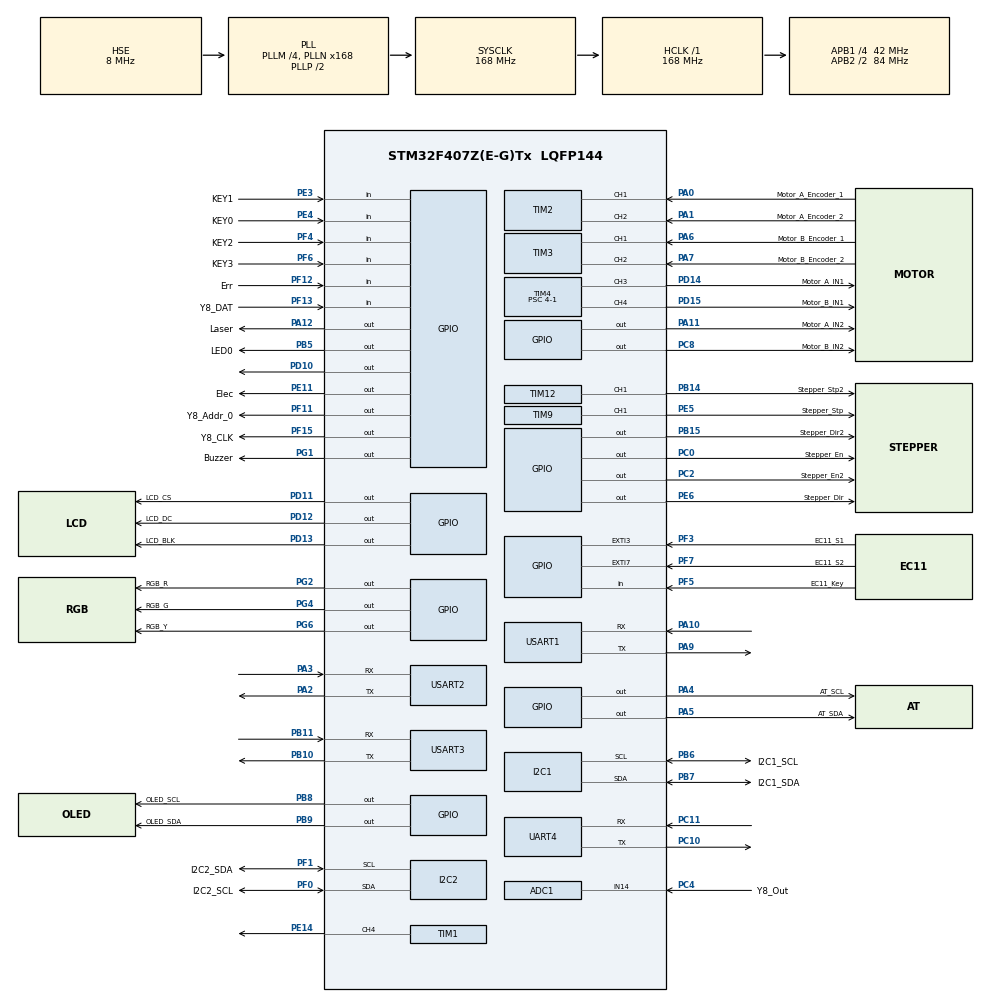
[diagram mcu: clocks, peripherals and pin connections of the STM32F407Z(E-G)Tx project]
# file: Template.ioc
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ADC1.Channel-1\#ChannelRegularConversion=ADC_CHANNEL_14
ADC1.NbrOfConversionFlag=1
ADC1.Rank-1\#ChannelRegularConversion=1
ADC1.SamplingTime-1\#ChannelRegularConversion=ADC_SAMPLETIME_3CYCLES
ADC1.master=1
Dma.Request0=USART1_RX
Dma.Request1=USART1_TX
Dma.Request2=USART2_RX
Dma.Request3=USART2_TX
Dma.Request4=UART4_RX
Dma.Request5=UART4_TX
Dma.Request6=USART3_RX
Dma.UART4_RX.4.Direction=DMA_PERIPH_TO_MEMORY
Dma.UART4_RX.4.FIFOMode=DMA_FIFOMODE_DISABLE
Dma.UART4_RX.4.Instance=DMA1_Stream2
Dma.UART4_RX.4.MemDataAlignment=DMA_MDATAALIGN_BYTE
Dma.UART4_RX.4.MemInc=DMA_MINC_ENABLE
Dma.UART4_RX.4.Mode=DMA_NORMAL
Dma.UART4_RX.4.PeriphDataAlignment=DMA_PDATAALIGN_BYTE
Dma.UART4_RX.4.PeriphInc=DMA_PINC_DISABLE
Dma.UART4_RX.4.Priority=DMA_PRIORITY_LOW
Dma.UART4_TX.5.Direction=DMA_MEMORY_TO_PERIPH
Dma.UART4_TX.5.FIFOMode=DMA_FIFOMODE_DISABLE
Dma.UART4_TX.5.Instance=DMA1_Stream4
Dma.UART4_TX.5.MemDataAlignment=DMA_MDATAALIGN_BYTE
Dma.UART4_TX.5.MemInc=DMA_MINC_ENABLE
Dma.UART4_TX.5.Mode=DMA_NORMAL
Dma.UART4_TX.5.PeriphDataAlignment=DMA_PDATAALIGN_BYTE
Dma.UART4_TX.5.PeriphInc=DMA_PINC_DISABLE
Dma.UART4_TX.5.Priority=DMA_PRIORITY_LOW
Dma.USART1_RX.0.Direction=DMA_PERIPH_TO_MEMORY
Dma.USART1_RX.0.FIFOMode=DMA_FIFOMODE_DISABLE
Dma.USART1_RX.0.Instance=DMA2_Stream2
Dma.USART1_RX.0.MemDataAlignment=DMA_MDATAALIGN_BYTE
Dma.USART1_RX.0.MemInc=DMA_MINC_ENABLE
Dma.USART1_RX.0.Mode=DMA_NORMAL
Dma.USART1_RX.0.PeriphDataAlignment=DMA_PDATAALIGN_BYTE
Dma.USART1_RX.0.PeriphInc=DMA_PINC_DISABLE
Dma.USART1_RX.0.Priority=DMA_PRIORITY_LOW
Dma.USART1_TX.1.Direction=DMA_MEMORY_TO_PERIPH
Dma.USART1_TX.1.FIFOMode=DMA_FIFOMODE_DISABLE
Dma.USART1_TX.1.Instance=DMA2_Stream7
Dma.USART1_TX.1.MemDataAlignment=DMA_MDATAALIGN_BYTE
Dma.USART1_TX.1.MemInc=DMA_MINC_ENABLE
Dma.USART1_TX.1.Mode=DMA_NORMAL
Dma.USART1_TX.1.PeriphDataAlignment=DMA_PDATAALIGN_BYTE
Dma.USART1_TX.1.PeriphInc=DMA_PINC_DISABLE
Dma.USART1_TX.1.Priority=DMA_PRIORITY_LOW
Dma.USART2_RX.2.Direction=DMA_PERIPH_TO_MEMORY
Dma.USART2_RX.2.FIFOMode=DMA_FIFOMODE_DISABLE
Dma.USART2_RX.2.Instance=DMA1_Stream5
Dma.USART2_RX.2.MemDataAlignment=DMA_MDATAALIGN_BYTE
Dma.USART2_RX.2.MemInc=DMA_MINC_ENABLE
Dma.USART2_RX.2.Mode=DMA_NORMAL
Dma.USART2_RX.2.PeriphDataAlignment=DMA_PDATAALIGN_BYTE
Dma.USART2_RX.2.PeriphInc=DMA_PINC_DISABLE
Dma.USART2_RX.2.Priority=DMA_PRIORITY_LOW
Dma.USART2_TX.3.Direction=DMA_MEMORY_TO_PERIPH
Dma.USART2_TX.3.FIFOMode=DMA_FIFOMODE_DISABLE
Dma.USART2_TX.3.Instance=DMA1_Stream6
Dma.USART2_TX.3.MemDataAlignment=DMA_MDATAALIGN_BYTE
Dma.USART2_TX.3.MemInc=DMA_MINC_ENABLE
Dma.USART2_TX.3.Mode=DMA_NORMAL
Dma.USART2_TX.3.PeriphDataAlignment=DMA_PDATAALIGN_BYTE
Dma.USART2_TX.3.PeriphInc=DMA_PINC_DISABLE
Dma.USART2_TX.3.Priority=DMA_PRIORITY_LOW
Dma.USART3_RX.6.Direction=DMA_PERIPH_TO_MEMORY
Dma.USART3_RX.6.FIFOMode=DMA_FIFOMODE_DISABLE
Dma.USART3_RX.6.Instance=DMA1_Stream1
Dma.USART3_RX.6.MemDataAlignment=DMA_MDATAALIGN_BYTE
Dma.USART3_RX.6.MemInc=DMA_MINC_ENABLE
Dma.USART3_RX.6.Mode=DMA_NORMAL
Dma.USART3_RX.6.PeriphDataAlignment=DMA_PDATAALIGN_BYTE
Dma.USART3_RX.6.PeriphInc=DMA_PINC_DISABLE
Dma.USART3_RX.6.Priority=DMA_PRIORITY_LOW
Mcu.Family=STM32F4
Mcu.Name=STM32F407Z(E-G)Tx
Mcu.Package=LQFP144
NVIC.DMA1_Stream1_IRQn=true\:0\:0\:false\:false\:true\:false\:true\:true
NVIC.DMA1_Stream2_IRQn=true\:0\:0\:false\:false\:true\:false\:true\:true
NVIC.DMA1_Stream4_IRQn=true\:0\:0\:false\:false\:true\:false\:true\:true
NVIC.DMA1_Stream5_IRQn=true\:0\:0\:false\:false\:true\:false\:true\:true
NVIC.DMA1_Stream6_IRQn=true\:0\:0\:false\:false\:true\:false\:true\:true
NVIC.DMA2_Stream2_IRQn=true\:0\:0\:false\:false\:true\:false\:true\:true
NVIC.DMA2_Stream7_IRQn=true\:0\:0\:false\:false\:true\:false\:true\:true
NVIC.EXTI3_IRQn=true\:0\:0\:false\:false\:true\:true\:true\:true
NVIC.EXTI9_5_IRQn=true\:0\:0\:false\:false\:true\:true\:true\:true
NVIC.PriorityGroup=NVIC_PRIORITYGROUP_2
NVIC.TIM1_UP_TIM10_IRQn=true\:0\:0\:false\:false\:true\:true\:true\:true
NVIC.TIM6_DAC_IRQn=true\:0\:0\:false\:false\:true\:true\:true\:true
NVIC.TIM7_IRQn=true\:0\:0\:false\:false\:true\:true\:true\:true
NVIC.UART4_IRQn=true\:0\:0\:false\:false\:true\:true\:true\:true
NVIC.USART1_IRQn=true\:0\:0\:false\:false\:true\:true\:true\:true
NVIC.USART2_IRQn=true\:0\:0\:false\:false\:true\:true\:true\:true
NVIC.USART3_IRQn=true\:0\:0\:false\:false\:true\:true\:true\:true
PA0-WKUP.GPIO_Label=Motor_A_Encoder_1
PA0-WKUP.Signal=S_TIM2_CH1_ETR
PA1.GPIO_Label=Motor_A_Encoder_2
PA1.Signal=S_TIM2_CH2
PA10.Mode=Asynchronous
PA10.Signal=USART1_RX
PA11.GPIO_Label=Motor_A_IN2
PA11.Signal=GPIO_Output
PA12.GPIO_Label=Laser
PA12.Signal=GPIO_Output
PA13.Mode=Serial_Wire
PA13.Signal=SYS_JTMS-SWDIO
PA14.Mode=Serial_Wire
PA14.Signal=SYS_JTCK-SWCLK
PA2.Mode=Asynchronous
PA2.Signal=USART2_TX
PA3.Mode=Asynchronous
PA3.Signal=USART2_RX
PA4.GPIO_Label=AT_SCL
PA4.Signal=GPIO_Output
PA5.GPIO_Label=AT_SDA
PA5.Signal=GPIO_Output
PA6.GPIO_Label=Motor_B_Encoder_1
PA6.Signal=S_TIM3_CH1
PA7.GPIO_Label=Motor_B_Encoder_2
PA7.Signal=S_TIM3_CH2
PA8.Signal=I2C3_SCL
PA9.Mode=Asynchronous
PA9.Signal=USART1_TX
PB10.Mode=Asynchronous
PB10.Signal=USART3_TX
PB11.Mode=Asynchronous
PB11.Signal=USART3_RX
PB14.GPIO_Label=Stepper_Stp2
PB14.Signal=S_TIM12_CH1
PB15.GPIO_Label=Stepper_Dir2
PB15.Signal=GPIO_Output
PB3.Signal=SPI3_SCK
PB5.GPIO_Label=LED0
PB5.Signal=GPIO_Output
PB6.GPIO_Label=I2C1_SCL
PB6.Mode=I2C
PB6.Signal=I2C1_SCL
PB7.GPIO_Label=I2C1_SDA
PB7.Mode=I2C
PB7.Signal=I2C1_SDA
PB8.GPIO_Label=OLED_SCL
PB8.GPIO_Speed=GPIO_SPEED_FREQ_HIGH
PB8.Signal=GPIO_Output
PB9.GPIO_Label=OLED_SDA
PB9.GPIO_Speed=GPIO_SPEED_FREQ_HIGH
PB9.Signal=GPIO_Output
PC0.GPIO_Label=Stepper_En
PC0.PinState=GPIO_PIN_SET
PC0.Signal=GPIO_Output
PC10.Mode=Asynchronous
PC10.Signal=UART4_TX
PC11.Mode=Asynchronous
PC11.Signal=UART4_RX
PC14-OSC32_IN.Mode=LSE-External-Oscillator
PC14-OSC32_IN.Signal=RCC_OSC32_IN
PC15-OSC32_OUT.Mode=LSE-External-Oscillator
PC15-OSC32_OUT.Signal=RCC_OSC32_OUT
PC2.GPIO_Label=Stepper_En2
PC2.PinState=GPIO_PIN_SET
PC2.Signal=GPIO_Output
PC4.GPIO_Label=Y8_Out
PC4.Signal=ADCx_IN14
PC6.Signal=USART6_TX
PC7.Signal=USART6_RX
PC8.GPIO_Label=Motor_B_IN2
PC8.Signal=GPIO_Output
PC9.Signal=I2C3_SDA
PD10.Signal=GPIO_Output
PD11.GPIO_Label=LCD_CS
PD11.Signal=GPIO_Output
PD12.GPIO_Label=LCD_DC
PD12.Signal=GPIO_Output
PD13.GPIO_Label=LCD_BLK
PD13.Signal=GPIO_Output
PD14.GPIO_Label=Motor_A_IN1
PD14.Signal=S_TIM4_CH3
PD15.GPIO_Label=Motor_B_IN1
PD15.Signal=S_TIM4_CH4
PE11.GPIO_Label=Elec
PE11.Signal=GPIO_Output
PE14.Signal=S_TIM1_CH4
PE3.GPIO_Label=KEY1
PE3.GPIO_Mode=GPIO_MODE_INPUT
PE3.GPIO_PuPd=GPIO_PULLUP
PE3.Signal=GPIO_Input
PE4.GPIO_Label=KEY0
PE4.GPIO_Mode=GPIO_MODE_INPUT
PE4.GPIO_PuPd=GPIO_PULLUP
PE4.Signal=GPIO_Input
PE5.GPIO_Label=Stepper_Stp
PE5.Signal=S_TIM9_CH1
PE6.GPIO_Label=Stepper_Dir
PE6.PinState=GPIO_PIN_SET
PE6.Signal=GPIO_Output
PF0.GPIO_Label=I2C2_SCL
PF0.Mode=I2C
PF0.Signal=I2C2_SDA
PF1.GPIO_Label=I2C2_SDA
PF1.Mode=I2C
PF1.Signal=I2C2_SCL
PF11.GPIO_Label=Y8_Addr_0
PF11.Signal=GPIO_Output
PF12.GPIO_Label=Err
PF12.Signal=GPIO_Input
PF13.GPIO_Label=Y8_DAT
PF13.GPIO_PuPd=GPIO_PULLUP
PF13.Signal=GPIO_Input
PF15.GPIO_Label=Y8_CLK
PF15.GPIO_Speed=GPIO_SPEED_FREQ_MEDIUM
PF15.Signal=GPIO_Output
PF3.GPIO_Label=EC11_S1
PF3.GPIO_ModeDefaultEXTI=GPIO_MODE_IT_FALLING
PF3.GPIO_PuPd=GPIO_PULLUP
PF3.Signal=GPXTI3
PF4.GPIO_Label=KEY2
PF4.GPIO_PuPd=GPIO_PULLUP
PF4.Signal=GPIO_Input
PF5.GPIO_Label=EC11_Key
PF5.GPIO_PuPd=GPIO_PULLUP
PF5.Signal=GPIO_Input
PF6.GPIO_Label=KEY3
PF6.GPIO_PuPd=GPIO_PULLUP
PF6.Signal=GPIO_Input
PF7.GPIO_Label=EC11_S2
PF7.GPIO_ModeDefaultEXTI=GPIO_MODE_IT_FALLING
PF7.GPIO_PuPd=GPIO_PULLUP
PF7.Signal=GPXTI7
PG1.GPIO_Label=Buzzer
PG1.PinState=GPIO_PIN_RESET
PG1.Signal=GPIO_Output
PG2.GPIO_Label=RGB_R
PG2.GPIO_ModeDefaultOutputPP=GPIO_MODE_OUTPUT_PP
PG2.GPIO_PuPd=GPIO_NOPULL
PG2.GPIO_Speed=GPIO_SPEED_FREQ_LOW
PG2.PinState=GPIO_PIN_RESET
PG2.Signal=GPIO_Output
PG4.GPIO_Label=RGB_G
PG4.GPIO_ModeDefaultOutputPP=GPIO_MODE_OUTPUT_PP
PG4.GPIO_PuPd=GPIO_NOPULL
PG4.GPIO_Speed=GPIO_SPEED_FREQ_LOW
PG4.PinState=GPIO_PIN_RESET
PG4.Signal=GPIO_Output
PG6.GPIO_Label=RGB_Y
PG6.GPIO_ModeDefaultOutputPP=GPIO_MODE_OUTPUT_PP
PG6.GPIO_PuPd=GPIO_NOPULL
PG6.GPIO_Speed=GPIO_SPEED_FREQ_LOW
PG6.PinState=GPIO_PIN_RESET
PG6.Signal=GPIO_Output
PH0-OSC_IN.Mode=HSE-External-Oscillator
PH0-OSC_IN.Signal=RCC_OSC_IN
PH1-OSC_OUT.Mode=HSE-External-Oscillator
PH1-OSC_OUT.Signal=RCC_OSC_OUT
ProjectManager.HeapSize=0x200
ProjectManager.StackSize=0x400
ProjectManager.TargetToolchain=MDK-ARM V5.32
RCC.48MHZClocksFreq_Value=84000000
RCC.AHBFreq_Value=168000000
RCC.APB1CLKDivider=RCC_HCLK_DIV4
RCC.APB1Freq_Value=42000000
RCC.APB1TimFreq_Value=84000000
RCC.APB2CLKDivider=RCC_HCLK_DIV2
RCC.APB2Freq_Value=84000000
RCC.APB2TimFreq_Value=168000000
RCC.CortexFreq_Value=168000000
RCC.HCLKFreq_Value=168000000
RCC.HSE_VALUE=8000000
RCC.HSI_VALUE=16000000
RCC.PLLM=4
RCC.PLLN=168
RCC.PLLSourceVirtual=RCC_PLLSOURCE_HSE
RCC.SYSCLKFreq_VALUE=168000000
RCC.SYSCLKSource=RCC_SYSCLKSOURCE_PLLCLK
RCC.VCOOutputFreq_Value=336000000
SH.ADCx_IN14.0=ADC1_IN14,IN14
SH.S_TIM12_CH1.0=TIM12_CH1,PWM Generation1 CH1
SH.S_TIM1_CH4.0=TIM1_CH4,PWM Generation4 CH4
SH.S_TIM2_CH1_ETR.0=TIM2_CH1,Encoder_Interface
SH.S_TIM2_CH2.0=TIM2_CH2,Encoder_Interface
SH.S_TIM3_CH1.0=TIM3_CH1,Encoder_Interface
SH.S_TIM3_CH2.0=TIM3_CH2,Encoder_Interface
SH.S_TIM4_CH3.0=TIM4_CH3,PWM Generation3 CH3
SH.S_TIM4_CH4.0=TIM4_CH4,PWM Generation4 CH4
SH.S_TIM9_CH1.0=TIM9_CH1,PWM Generation1 CH1
TIM1.Channel-PWM\ Generation4\ CH4=TIM_CHANNEL_4
TIM1.Period=19999
TIM1.Prescaler=167
TIM10.Period=10000-1
TIM10.Prescaler=168-1
TIM12.AutoReloadPreload=TIM_AUTORELOAD_PRELOAD_ENABLE
TIM12.Channel-PWM\ Generation1\ CH1=TIM_CHANNEL_1
TIM12.Period=1000-1
TIM12.Prescaler=84-1
TIM2.EncoderMode=TIM_ENCODERMODE_TI12
TIM3.EncoderMode=TIM_ENCODERMODE_TI12
TIM4.Channel-PWM\ Generation3\ CH3=TIM_CHANNEL_3
TIM4.Channel-PWM\ Generation4\ CH4=TIM_CHANNEL_4
TIM4.Period=1000-1
TIM4.Prescaler=4-1
TIM6.AutoReloadPreload=TIM_AUTORELOAD_PRELOAD_ENABLE
TIM6.Period=1000-1
TIM6.Prescaler=84-1
TIM7.AutoReloadPreload=TIM_AUTORELOAD_PRELOAD_ENABLE
TIM7.Period=20000-1
TIM7.Prescaler=84-1
TIM9.AutoReloadPreload=TIM_AUTORELOAD_PRELOAD_ENABLE
TIM9.Channel-PWM\ Generation1\ CH1=TIM_CHANNEL_1
TIM9.Period=1000-1
TIM9.Prescaler=168-1
UART4.VirtualMode=Asynchronous
USART1.VirtualMode=VM_ASYNC
USART2.VirtualMode=VM_ASYNC
USART3.VirtualMode=VM_ASYNC
VP_TIM10_VS_ClockSourceINT.Mode=Enable_Timer
VP_TIM12_VS_ClockSourceINT.Mode=Internal
VP_TIM1_VS_ClockSourceINT.Mode=Internal
VP_TIM4_VS_ClockSourceINT.Mode=Internal
VP_TIM6_VS_ClockSourceINT.Mode=Enable_Timer
VP_TIM7_VS_ClockSourceINT.Mode=Enable_Timer
VP_TIM9_VS_ClockSourceINT.Mode=Internal
board=custom

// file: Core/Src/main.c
/* USER CODE BEGIN Header */
/**
  ******************************************************************************
  * @file           : main.c
  * @brief          : Main program body
  ******************************************************************************
  * @attention
  *
  * Copyright (c) 2026 STMicroelectronics.
  * All rights reserved.
  *
  * This software is licensed under terms that can be found in the LICENSE file
  * in the root directory of this software component.
  * If no LICENSE file comes with this software, it is provided AS-IS.
  *
  ******************************************************************************
  */
/* USER CODE END Header */
#include "main.h"
#include "adc.h"
#include "dma.h"
#include "i2c.h"
#include "tim.h"
#include "usart.h"
#include "gpio.h"

/* USER CODE BEGIN Includes */
#include "Mymain.h"
/* USER CODE END Includes */

void SystemClock_Config(void);

int main(void)
{

  /* MCU Configuration--------------------------------------------------------*/

  /* Reset of all peripherals, Initializes the Flash interface and the Systick. */
  HAL_Init();

  /* Configure the system clock */
  SystemClock_Config();

  /* Initialize all configured peripherals */
  MX_GPIO_Init();
  MX_DMA_Init();
  MX_ADC1_Init();
  MX_I2C1_Init();
  MX_I2C2_Init();
  MX_TIM2_Init();
  MX_TIM3_Init();
  MX_TIM4_Init();
  MX_TIM6_Init();
  MX_TIM7_Init();
  MX_TIM9_Init();
  MX_TIM12_Init();
  MX_USART1_UART_Init();
  MX_USART2_UART_Init();
  MX_UART4_Init();
  MX_USART3_UART_Init();
  MX_TIM10_Init();
  MX_TIM1_Init();
  /* USER CODE BEGIN 2 */
	Mymain() ;
  /* USER CODE END 2 */

  /* Infinite loop */
  while (1)
  {

  }
}

void SystemClock_Config(void)
{
  RCC_OscInitTypeDef RCC_OscInitStruct = {0};
  RCC_ClkInitTypeDef RCC_ClkInitStruct = {0};

  /** Configure the main internal regulator output voltage
  */
  __HAL_RCC_PWR_CLK_ENABLE();
  __HAL_PWR_VOLTAGESCALING_CONFIG(PWR_REGULATOR_VOLTAGE_SCALE1);

  /** Initializes the RCC Oscillators according to the specified parameters
  * in the RCC_OscInitTypeDef structure.
  */
  RCC_OscInitStruct.OscillatorType = RCC_OSCILLATORTYPE_HSE;
  RCC_OscInitStruct.HSEState = RCC_HSE_ON;
  RCC_OscInitStruct.PLL.PLLState = RCC_PLL_ON;
  RCC_OscInitStruct.PLL.PLLSource = RCC_PLLSOURCE_HSE;
  RCC_OscInitStruct.PLL.PLLM = 4;
  RCC_OscInitStruct.PLL.PLLN = 168;
  RCC_OscInitStruct.PLL.PLLP = RCC_PLLP_DIV2;
  RCC_OscInitStruct.PLL.PLLQ = 4;
  if (HAL_RCC_OscConfig(&RCC_OscInitStruct) != HAL_OK)
  {
    Error_Handler();
  }

  /** Initializes the CPU, AHB and APB buses clocks
  */
  RCC_ClkInitStruct.ClockType = RCC_CLOCKTYPE_HCLK|RCC_CLOCKTYPE_SYSCLK
                              |RCC_CLOCKTYPE_PCLK1|RCC_CLOCKTYPE_PCLK2;
  RCC_ClkInitStruct.SYSCLKSource = RCC_SYSCLKSOURCE_PLLCLK;
  RCC_ClkInitStruct.AHBCLKDivider = RCC_SYSCLK_DIV1;
  RCC_ClkInitStruct.APB1CLKDivider = RCC_HCLK_DIV4;
  RCC_ClkInitStruct.APB2CLKDivider = RCC_HCLK_DIV2;

  if (HAL_RCC_ClockConfig(&RCC_ClkInitStruct, FLASH_LATENCY_5) != HAL_OK)
  {
    Error_Handler();
  }
}

void Error_Handler(void)
{
  __disable_irq();
  while (1)
  {
  }
}
